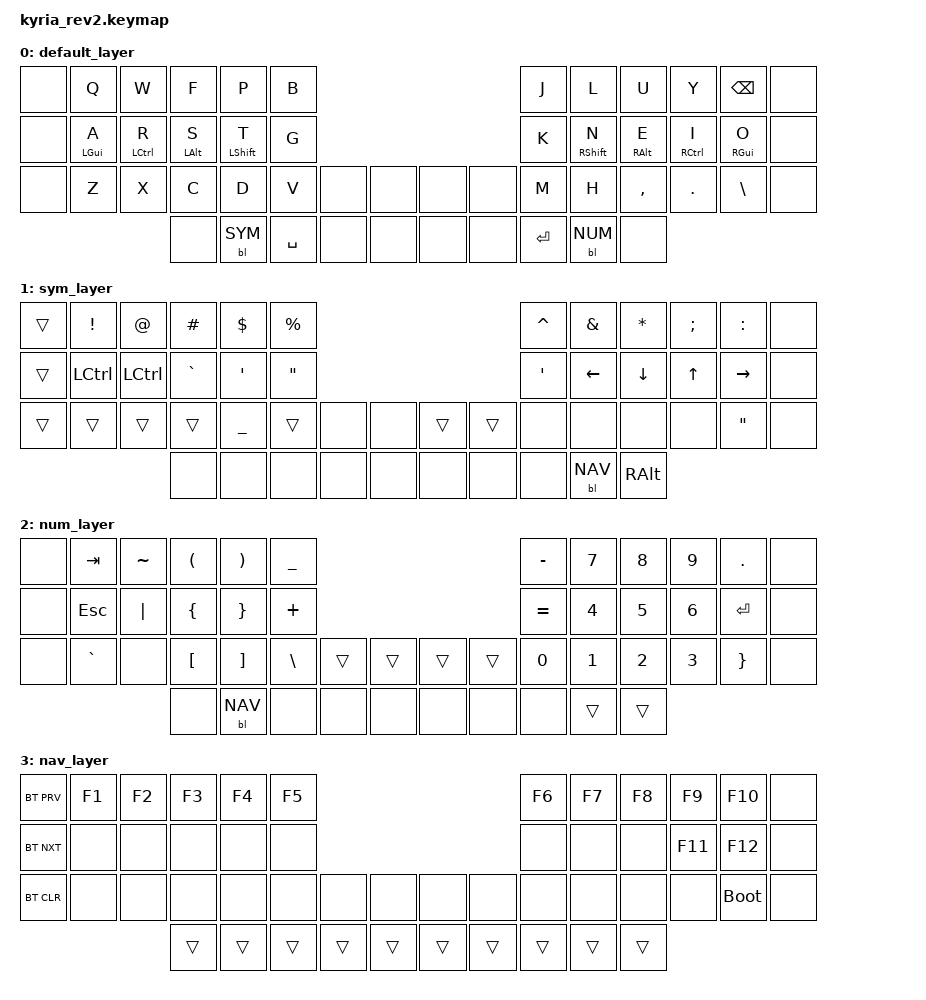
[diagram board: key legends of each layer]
/*
 * Copyright (c) 2020 The ZMK Contributors
 *
 * SPDX-License-Identifier: MIT
 */

#include <behaviors.dtsi>
#include <dt-bindings/zmk/keys.h>
#include <dt-bindings/zmk/bt.h>

#define DEFAULT 0
#define SYM     1
#define NUM     2
#define NAV     3

/ {
  combos {

  };

  behaviors {
    hm: homerow_mods {
      compatible = "zmk,behavior-hold-tap";
      label = "HOMEROW_MODS";
      #binding-cells = <2>;
      tapping-term-ms = <200>;
      quick_tap_ms = <0>;
      flavor = "tap-preferred";
      bindings = <&kp>, <&kp>;
    };
    hs: homerow_shifts {
      compatible = "zmk,behavior-hold-tap";
      label = "HOMEROW_SHIFTS";
      #binding-cells = <2>;
      tapping-term-ms = <150>;
      quick_tap_ms = <0>;
      flavor = "balanced";
      bindings = <&kp>, <&kp>;
    };
    hsl: homerow_shifts_layer {
      compatible = "zmk,behavior-hold-tap";
      label = "HOMEROW_SHIFTS_LAYER";
      #binding-cells = <2>;
      tapping-term-ms = <150>;
      quick_tap_ms = <0>;
      flavor = "balanced";
      bindings = <&kp>, <&to>;
    };
    td: tapdance {
      compatible = "zmk,behavior-hold-tap";
      label = "TAPDANCE";
      #binding-cells = <2>;
      tapping-term-ms = <150>;
      quick_tap_ms = <0>;
      flavor = "tap-preferred";
      bindings = <&kp>, <&kp>;
    };
    bl: layertap {
      compatible = "zmk,behavior-hold-tap";
      label = "LAYERTAP";
      #binding-cells = <2>;
      tapping-term-ms = <150>;
      quick_tap_ms = <0>;
      flavor = "tap-preferred";
      bindings = <&to>, <&kp>;
    };
  };

  keymap {
    compatible = "zmk,keymap";

    default_layer {
      bindings = <
// +---------+----------+----------+------------+------------+------------+                                                    +------------+------------+------------+------------+------------+---------+
// |         |          |          |            |            |            |                                                    |            |            |            |            |            |         |
   &none     &kp Q      &kp W      &kp F        &kp P        &kp B                                                             &kp J        &kp L        &kp U        &kp Y        &kp BSPC     &none   
   &none     &hm LGUI A &hm LCTL R &hm LALT S   &hm LSHIFT T &kp G                                                             &kp K        &hm RSHIFT N &hm RALT E   &hm RCTL I   &hm RGUI O   &none   
   &none     &kp Z      &kp X      &kp C        &kp D        &kp V        &none      &none             &none        &none      &kp M        &kp H        &kp COMMA    &kp DOT      &kp BSLH     &none   
// +---------+----------+----------+------------+------------+------------+----------+-----------+     +------------+----------+------------+------------+------------+------------+------------+---------+
                                   &none        &bl SYM      &kp SPC      &none      &none             &none        &none      &kp RET      &bl NUM      &none   
//                                 |            |            |            |          |           |     |            |          |            |            |            |
//                                 +------------+------------+------------+----------+-----------+     +------------+----------+------------+------------+------------+
      >;
    };

    sym_layer {
      bindings = <
// +---------+------------+------------+------------+------------+------------+                                                      +------------+------------+------------+------------+------------+----------+
// |         |            |            |            |            |            |                                                      |            |            |            |            |            |          |
   &trans    &kp EXCL     &kp AT       &kp HASH     &kp DOLLAR   &kp PRCNT                                                           &kp CARET    &kp AMPS     &kp STAR     &kp SEMI     &kp COLON    &none   
   &trans    &kp LCTRL    &kp LCTRL    &kp GRAVE    &kp APOS     &kp DQT                                                             &kp SQT      &kp LEFT     &kp DOWN     &kp UP       &kp RIGHT    &none   
   &trans    &trans       &trans       &trans       &kp UNDER    &trans       &none        &none             &trans       &trans     &none        &none        &none        &none        &kp DQT      &none   
// +---------+------------+------------+------------+------------+------------+------------+-----------+     +------------+----------+------------+------------+------------+------------+------------+----------+
                                       &none        &none        &none        &none        &none             &none        &none      &none        &bl NAV      &kp RALT
//                                     |            |            |            |            |           |     |            |          |            |            |            |
//                                     +------------+------------+------------+------------+-----------+     +------------+----------+------------+------------+------------+
      >;
    };

    num_layer {
      bindings = <
// +------------+----------+------------+------------+------------+------------+                                                       +------------+----------+------------+----------+------------+----------+
// |            |          |            |            |            |            |                                                       |            |          |            |          |            |          |
   &none        &kp TAB    &kp TILDE    &kp LPAR     &kp RPAR     &kp UNDER                                                            &kp MINUS    &kp N7     &kp N8       &kp N9     &kp DOT      &none   
   &none        &kp ESC    &kp PIPE     &kp LBRC     &kp RBRC     &kp PLUS                                                             &kp EQUAL    &kp N4     &kp N5       &kp N6     &kp RET      &none   
   &none        &kp GRAVE  &none        &kp LBKT     &kp RBKT     &kp BSLH     &trans       &trans             &trans       &trans     &kp N0       &kp N1     &kp N2       &kp N3     &kp RBRC     &none   
// +------------+----------+------------+------------+------------+------------+------------+------------+     +------------+----------+------------+----------+------------+----------+------------+----------+
                                        &none        &bl NAV      &none        &none        &none              &none        &none      &none        &trans     &trans
//                                      |            |            |            |            |            |     |            |          |            |          |            |
//                                      +------------+------------+------------+------------+------------+     +------------+----------+------------+----------+------------+
      >;
    };

    nav_layer {
      bindings = <
// +------------+----------+------------+------------+------------+------------+                                                        +------------+----------+------------+----------+------------+----------+
// |            |          |            |            |            |            |                                                        |            |          |            |          |            |          |
   &bt BT_PRV   &kp F1     &kp F2       &kp F3       &kp F4       &kp F5                                                                &kp F6       &kp F7     &kp F8       &kp F9     &kp F10      &none
   &bt BT_NXT   &none      &none        &none        &none        &none                                                                 &none        &none      &none        &kp F11    &kp F12      &none
   &bt BT_CLR   &none      &none        &none        &none        &none        &none        &none              &none        &none       &none        &none      &none        &none      &bootloader  &none
// +------------+----------+------------+------------+------------+------------+------------+------------+     +------------+-----------+------------+----------+------------+----------+------------+----------+
                                        &trans       &trans       &trans       &trans       &trans             &trans       &trans      &trans       &trans     &trans
//                                      |            |            |            |            |            |     |            |           |            |          |            |
//                                      +------------+------------+------------+------------+------------+     +------------+-----------+------------+----------+------------+
      >;
    };
  };
};
